# K1921VG015 register map
Vendor: NIIET; Series: K1921Vxxx; File version: 1.12
Registers are 32-bit, read-write, reset 0x0 unless marked. A register's access mark holds for its fields unless they carry their own. Offsets are from the block's base; [hi:lo] are bit positions; lines under a group give offsets from that group; {n}, {i} and the like mark numbered series.

## GPIOA — GPIO control registers
Base 0x28000000
Same registers: GPIOB 0x28001000, GPIOC 0x28002000
0x00 DATA ro — Data Input register
  [15:0] VAL
0x04 DATAOUT — Data output register
  [15:0] VAL
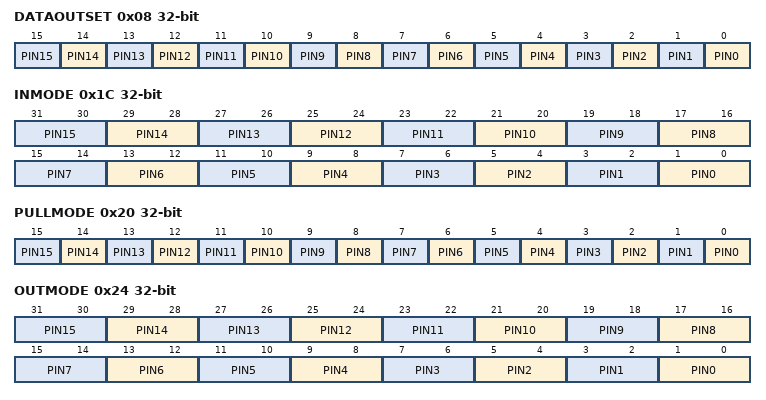
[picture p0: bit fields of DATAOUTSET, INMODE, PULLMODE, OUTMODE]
0x08 DATAOUTSET wo — Data output set bits register
  [n] PIN{n} (n=0..15) — Data output set bit {n}
0x0C DATAOUTCLR wo — Data output clear bits register
  [15:0] VAL — Data output clear
0x10 DATAOUTTGL wo — Data output toggle bits register
  [15:0] VAL — Data output toggle
0x1C INMODE — Select input mode register
  [all] fields
    0=Schmitt (Scmitt buffer); 3=Disable (Input buffer disabled)
  [2n+1:2n] PIN{n} (n=0..15) — Select input mode for pin {n}
0x20 PULLMODE — Select pull mode register
  [all] fields
    0=Disable (Pull disabled); 1=PU (Pull-up)
  [n] PIN{n} (n=0..15) — Select pull mode for pin {n}
0x24 OUTMODE — Select output mode register
  [all] fields
    0=PP (Push-pull output); 1=OD (Open drain output); 2=OS (Open source output)
  [2n+1:2n] PIN{n} (n=0..15) — Select output mode for pin {n}
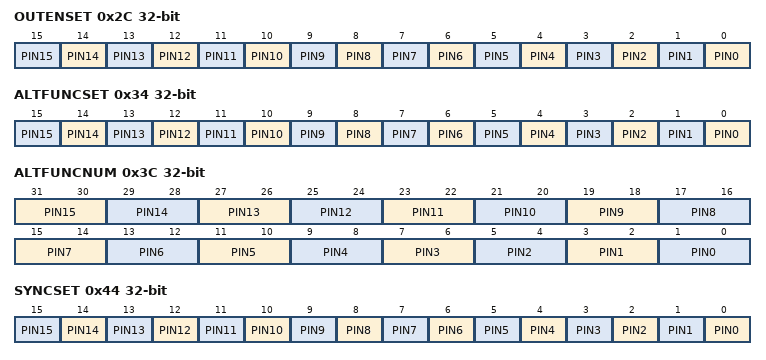
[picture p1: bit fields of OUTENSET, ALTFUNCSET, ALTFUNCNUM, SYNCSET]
0x2C OUTENSET — Output enable register
  [n] PIN{n} (n=0..15) — Output enable for pin {n}
0x30 OUTENCLR wo — Output disable register
  [15:0] VAL — Output disable
0x34 ALTFUNCSET — Alternative function enable register
  [n] PIN{n} (n=0..15) — Alternative function enable for pin {n}
0x38 ALTFUNCCLR wo — Alternative function disable register
  [15:0] VAL — Alternative function disable
0x3C ALTFUNCNUM — Alternative function number register
  [all] fields
    0=Disable (Altfunc disabled); 1=AF1 (Altfunc 1 enable); 2=AF2 (Altfunc 2 enable); 3=AF3 (Altfunc 3 enable)
  [31:30] PIN15 — Select altfunc number for pin 7
  [29:28] PIN14 — Select altfunc number for pin 7
  [27:26] PIN13 — Select altfunc number for pin 6
  [25:24] PIN12 — Select altfunc number for pin 6
  [23:22] PIN11 — Select altfunc number for pin 5
  [21:20] PIN10 — Select altfunc number for pin 5
  [19:18] PIN9 — Select altfunc number for pin 4
  [17:16] PIN8 — Select altfunc number for pin 4
  [15:14] PIN7 — Select altfunc number for pin 3
  [13:12] PIN6 — Select altfunc number for pin 3
  [11:10] PIN5 — Select altfunc number for pin 2
  [9:8] PIN4 — Select altfunc number for pin 2
  [7:6] PIN3 — Select altfunc number for pin 1
  [5:4] PIN2 — Select altfunc number for pin 1
  [3:2] PIN1 — Select altfunc number for pin 0
  [1:0] PIN0 — Select altfunc number for pin 0
0x44 SYNCSET — Additional double flip-flop syncronization enable register
  [n] PIN{n} (n=0..15) — Additional double flip-flop syncronization buffer enable for pin {n}
0x48 SYNCCLR wo — Additional double flip-flop syncronization disable register
  [15:0] VAL — Additional double flip-flop syncronization disable
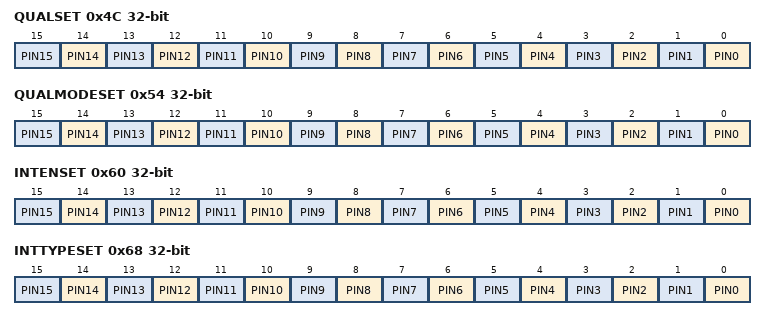
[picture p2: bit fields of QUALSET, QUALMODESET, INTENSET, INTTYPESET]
0x4C QUALSET — Qualifier enable register
  [n] PIN{n} (n=0..15) — Qualifier enable for pin {n}
0x50 QUALCLR wo — Qualifier disable register
  [15:0] VAL — Qualifier disable
0x54 QUALMODESET — Qualifier mode set register
  [n] PIN{n} (n=0..15) — Qualifier mode set for pin {n}
0x58 QUALMODECLR wo — Qualifier mode clear register
  [15:0] VAL — Qualifier mode clear
0x5C QUALSAMPLE — Qualifier sample period register
  [19:0] VAL — Qualifier sample period
0x60 INTENSET — Interrupt enable register
  [n] PIN{n} (n=0..15) — Interrupt enable for pin {n}
0x64 INTENCLR wo — Interrupt disable register
  [15:0] VAL — Interrupt disable
0x68 INTTYPESET — Interrupt type set register
  [n] PIN{n} (n=0..15) — Interrupt type set for pin {n}
0x6C INTTYPECLR wo — Interrupt type clear register
  [15:0] VAL — Interrupt type clear
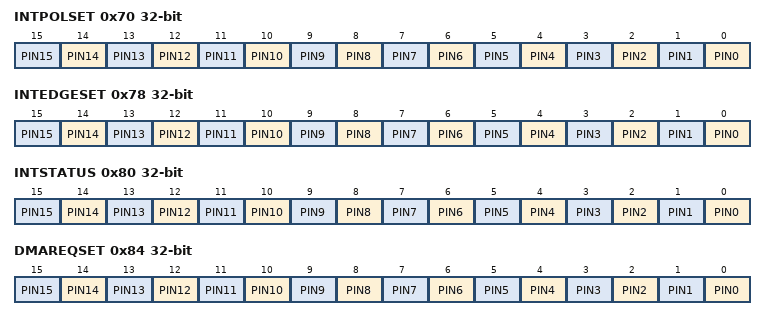
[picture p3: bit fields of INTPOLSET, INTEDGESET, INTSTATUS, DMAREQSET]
0x70 INTPOLSET — Interrupt polarity set register
  [n] PIN{n} (n=0..15) — Interrupt polarity set for pin {n}
0x74 INTPOLCLR wo — Interrupt polarity clear register
  [15:0] VAL — Interrupt polarity clear
0x78 INTEDGESET — Interrupt every edge set register
  [n] PIN{n} (n=0..15) — Interrupt every edge set for pin {n}
0x7C INTEDGECLR wo — Interrupt every edge clear register
  [15:0] VAL — Interrupt every edge clear
0x80 INTSTATUS — Interrupt status
  [n] PIN{n} (n=0..15) — Interrupt status of pin {n}
0x84 DMAREQSET — DMA request enable register
  [n] PIN{n} (n=0..15) — DMA request enable for pin {n}
0x88 DMAREQCLR wo — DMA request disable register
  [15:0] VAL — DMA request disable
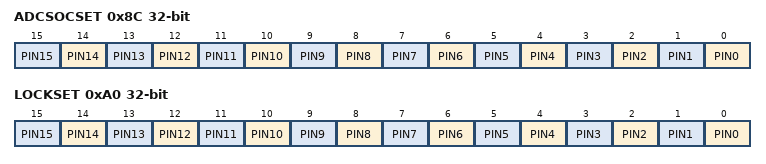
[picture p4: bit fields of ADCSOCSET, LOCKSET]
0x8C ADCSOCSET — ADC Start Of Conversion enable register
  [n] PIN{n} (n=0..15) — ADC SOC enable for pin {n}
0x90 ADCSOCCLR wo — ADC Start Of Conversion disable register
  [15:0] VAL — ADC SOC disable
0x9C LOCKKEY wo — Key register to unlock LOCKSET/LOCKCLR registers for write (KEY=0xADEADBEE)
  [31:0] VAL — Key to unlock LOCKSET/LOCKCLR registers for write (KEY=0xADEADBEE)
    on write: 0xEEEEEEEE=LOCK (key to lock registers); 0xADEADBEE=UNLOCK (key to unlock registers)
0xA0 LOCKSET — Lock pins configuration enable register
  [n] PIN{n} (n=0..15) — Lock configuration enable for pin {n}
0xA4 LOCKCLR wo — Lock pins configuration disable register
  [15:0] VAL — Lock configuration disable
{0x400+4i} MASKLB[{i}] (i=0..255) group
  0x00 MASKLB — Mask register low byte of port
    [7:0] VAL — Mask low byte
{0x800+4i} MASKHB[{i}] (i=0..255) group
  0x00 MASKHB — Mask register High byte of port
    [15:8] VAL — Mask high byte
